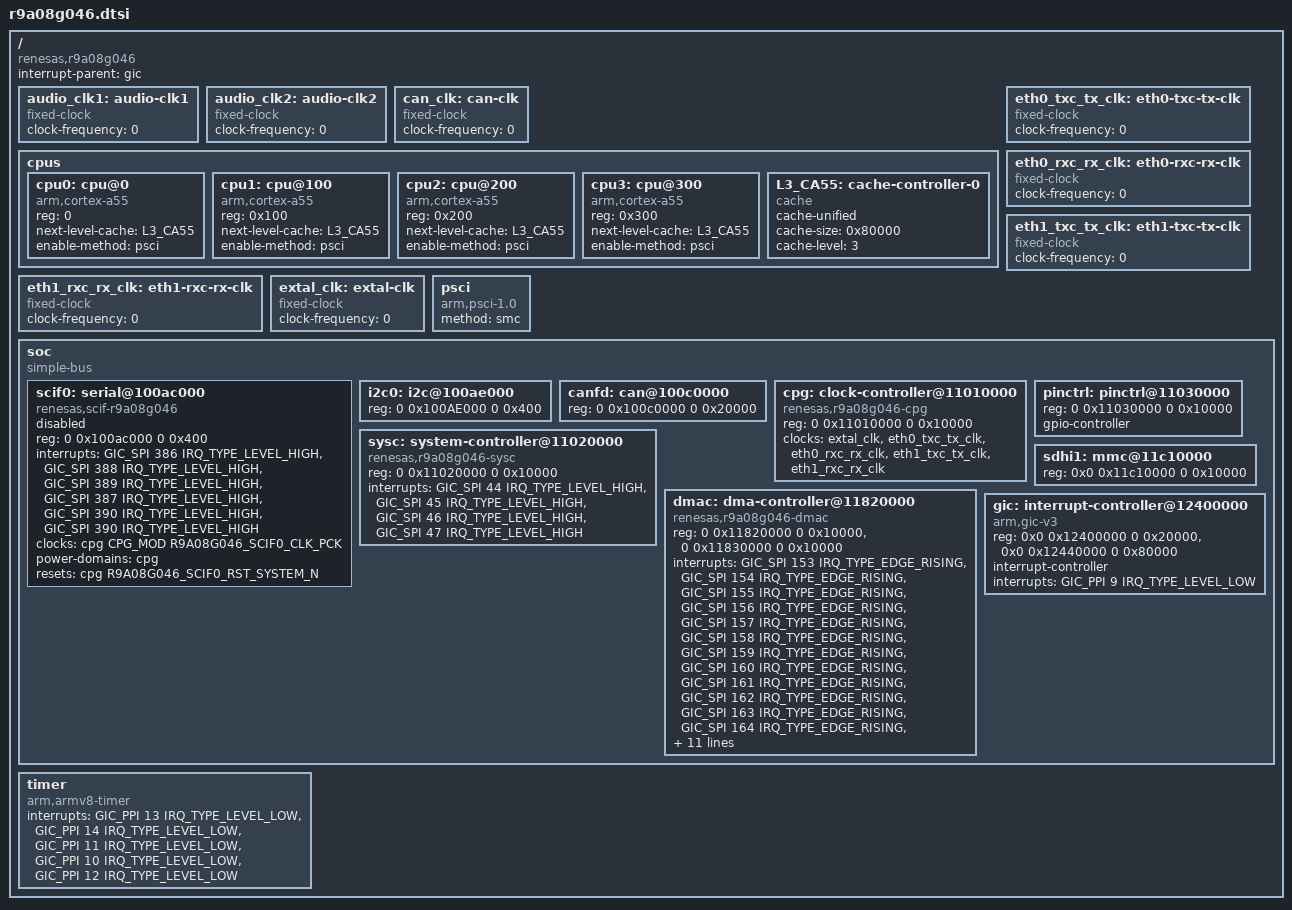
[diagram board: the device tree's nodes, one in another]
// SPDX-License-Identifier: (GPL-2.0-only OR BSD-2-Clause)
/*
 * Device Tree Source for the RZ/G3L SoC
 *
 * Copyright (C) 2026 Renesas Electronics Corp.
 */

#include <dt-bindings/clock/r9a08g046-cpg.h>
#include <dt-bindings/interrupt-controller/arm-gic.h>

/ {
	compatible = "renesas,r9a08g046";
	#address-cells = <2>;
	#size-cells = <2>;
	interrupt-parent = <&gic>;

	audio_clk1: audio-clk1 {
		compatible = "fixed-clock";
		#clock-cells = <0>;
		/* This value must be overridden by boards that provide it. */
		clock-frequency = <0>;
	};

	audio_clk2: audio-clk2 {
		compatible = "fixed-clock";
		#clock-cells = <0>;
		/* This value must be overridden by boards that provide it. */
		clock-frequency = <0>;
	};

	can_clk: can-clk {
		compatible = "fixed-clock";
		#clock-cells = <0>;
		/* This value must be overridden by boards that provide it. */
		clock-frequency = <0>;
	};

	cpus {
		#address-cells = <1>;
		#size-cells = <0>;

		cpu0: cpu@0 {
			compatible = "arm,cortex-a55";
			reg = <0>;
			device_type = "cpu";
			next-level-cache = <&L3_CA55>;
			enable-method = "psci";
		};

		cpu1: cpu@100 {
			compatible = "arm,cortex-a55";
			reg = <0x100>;
			device_type = "cpu";
			next-level-cache = <&L3_CA55>;
			enable-method = "psci";
		};

		cpu2: cpu@200 {
			compatible = "arm,cortex-a55";
			reg = <0x200>;
			device_type = "cpu";
			next-level-cache = <&L3_CA55>;
			enable-method = "psci";
		};

		cpu3: cpu@300 {
			compatible = "arm,cortex-a55";
			reg = <0x300>;
			device_type = "cpu";
			next-level-cache = <&L3_CA55>;
			enable-method = "psci";
		};

		L3_CA55: cache-controller-0 {
			compatible = "cache";
			cache-unified;
			cache-size = <0x80000>;
			cache-level = <3>;
		};
	};

	eth0_txc_tx_clk: eth0-txc-tx-clk {
		compatible = "fixed-clock";
		#clock-cells = <0>;
		/* This value must be overridden by the board */
		clock-frequency = <0>;
	};

	eth0_rxc_rx_clk: eth0-rxc-rx-clk {
		compatible = "fixed-clock";
		#clock-cells = <0>;
		/* This value must be overridden by the board */
		clock-frequency = <0>;
	};

	eth1_txc_tx_clk: eth1-txc-tx-clk {
		compatible = "fixed-clock";
		#clock-cells = <0>;
		/* This value must be overridden by the board */
		clock-frequency = <0>;
	};

	eth1_rxc_rx_clk: eth1-rxc-rx-clk {
		compatible = "fixed-clock";
		#clock-cells = <0>;
		/* This value must be overridden by the board */
		clock-frequency = <0>;
	};

	extal_clk: extal-clk {
		compatible = "fixed-clock";
		#clock-cells = <0>;
		/* This value must be overridden by the board. */
		clock-frequency = <0>;
	};

	psci {
		compatible = "arm,psci-1.0", "arm,psci-0.2";
		method = "smc";
	};

	soc: soc {
		compatible = "simple-bus";
		#address-cells = <2>;
		#size-cells = <2>;
		ranges;

		scif0: serial@100ac000 {
			compatible = "renesas,scif-r9a08g046", "renesas,scif-r9a07g044";
			reg = <0 0x100ac000 0 0x400>;
			interrupts = <GIC_SPI 386 IRQ_TYPE_LEVEL_HIGH>,
				     <GIC_SPI 388 IRQ_TYPE_LEVEL_HIGH>,
				     <GIC_SPI 389 IRQ_TYPE_LEVEL_HIGH>,
				     <GIC_SPI 387 IRQ_TYPE_LEVEL_HIGH>,
				     <GIC_SPI 390 IRQ_TYPE_LEVEL_HIGH>,
				     <GIC_SPI 390 IRQ_TYPE_LEVEL_HIGH>;
			interrupt-names = "eri", "rxi", "txi",
					  "bri", "dri", "tei";
			clocks = <&cpg CPG_MOD R9A08G046_SCIF0_CLK_PCK>;
			clock-names = "fck";
			power-domains = <&cpg>;
			resets = <&cpg R9A08G046_SCIF0_RST_SYSTEM_N>;
			status = "disabled";
		};

		i2c0: i2c@100ae000 {
			#address-cells = <1>;
			#size-cells = <0>;
			reg = <0 0x100AE000 0 0x400>;
			/* placeholder */
		};

		canfd: can@100c0000 {
			reg = <0 0x100c0000 0 0x20000>;
			/* placeholder */
		};

		cpg: clock-controller@11010000 {
			compatible = "renesas,r9a08g046-cpg";
			reg = <0 0x11010000 0 0x10000>;
			clocks = <&extal_clk>,
				 <&eth0_txc_tx_clk>, <&eth0_rxc_rx_clk>,
				 <&eth1_txc_tx_clk>, <&eth1_rxc_rx_clk>;
			clock-names = "extal",
				      "eth0_txc_tx_clk", "eth0_rxc_rx_clk",
				      "eth1_txc_tx_clk", "eth1_rxc_rx_clk";
			#clock-cells = <2>;
			#reset-cells = <1>;
			#power-domain-cells = <0>;
		};

		sysc: system-controller@11020000 {
			compatible = "renesas,r9a08g046-sysc";
			reg = <0 0x11020000 0 0x10000>;
			interrupts = <GIC_SPI 44 IRQ_TYPE_LEVEL_HIGH>,
				     <GIC_SPI 45 IRQ_TYPE_LEVEL_HIGH>,
				     <GIC_SPI 46 IRQ_TYPE_LEVEL_HIGH>,
				     <GIC_SPI 47 IRQ_TYPE_LEVEL_HIGH>;
			interrupt-names = "lpm_int", "ca55stbydone_int",
					  "cm33stbyr_int", "ca55_deny";
		};

		pinctrl: pinctrl@11030000 {
			reg = <0 0x11030000 0 0x10000>;
			gpio-controller;
			#gpio-cells = <2>;
		};

		dmac: dma-controller@11820000 {
			compatible = "renesas,r9a08g046-dmac", "renesas,rz-dmac";
			reg = <0 0x11820000 0 0x10000>,
			      <0 0x11830000 0 0x10000>;
			interrupts = <GIC_SPI 153 IRQ_TYPE_EDGE_RISING>,
				     <GIC_SPI 154 IRQ_TYPE_EDGE_RISING>,
				     <GIC_SPI 155 IRQ_TYPE_EDGE_RISING>,
				     <GIC_SPI 156 IRQ_TYPE_EDGE_RISING>,
				     <GIC_SPI 157 IRQ_TYPE_EDGE_RISING>,
				     <GIC_SPI 158 IRQ_TYPE_EDGE_RISING>,
				     <GIC_SPI 159 IRQ_TYPE_EDGE_RISING>,
				     <GIC_SPI 160 IRQ_TYPE_EDGE_RISING>,
				     <GIC_SPI 161 IRQ_TYPE_EDGE_RISING>,
				     <GIC_SPI 162 IRQ_TYPE_EDGE_RISING>,
				     <GIC_SPI 163 IRQ_TYPE_EDGE_RISING>,
				     <GIC_SPI 164 IRQ_TYPE_EDGE_RISING>,
				     <GIC_SPI 165 IRQ_TYPE_EDGE_RISING>,
				     <GIC_SPI 166 IRQ_TYPE_EDGE_RISING>,
				     <GIC_SPI 167 IRQ_TYPE_EDGE_RISING>,
				     <GIC_SPI 168 IRQ_TYPE_EDGE_RISING>,
				     <GIC_SPI 169 IRQ_TYPE_EDGE_RISING>;
			interrupt-names = "error",
					  "ch0", "ch1", "ch2", "ch3",
					  "ch4", "ch5", "ch6", "ch7",
					  "ch8", "ch9", "ch10", "ch11",
					  "ch12", "ch13", "ch14", "ch15";
			clocks = <&cpg CPG_MOD R9A08G046_DMAC_ACLK>,
				 <&cpg CPG_MOD R9A08G046_DMAC_PCLK>;
			clock-names = "main", "register";
			power-domains = <&cpg>;
			resets = <&cpg R9A08G046_DMAC_ARESETN>,
				 <&cpg R9A08G046_DMAC_RST_ASYNC>;
			reset-names = "arst", "rst_async";
			#dma-cells = <1>;
			dma-channels = <16>;
		};

		sdhi1: mmc@11c10000 {
			reg = <0x0 0x11c10000 0 0x10000>;
			/* placeholder */
		};

		gic: interrupt-controller@12400000 {
			compatible = "arm,gic-v3";
			reg = <0x0 0x12400000 0 0x20000>,
			      <0x0 0x12440000 0 0x80000>;
			#interrupt-cells = <3>;
			#address-cells = <0>;
			interrupt-controller;
			interrupts = <GIC_PPI 9 IRQ_TYPE_LEVEL_LOW>;
		};
	};

	timer {
		compatible = "arm,armv8-timer";
		interrupts = <GIC_PPI 13 IRQ_TYPE_LEVEL_LOW>,
			     <GIC_PPI 14 IRQ_TYPE_LEVEL_LOW>,
			     <GIC_PPI 11 IRQ_TYPE_LEVEL_LOW>,
			     <GIC_PPI 10 IRQ_TYPE_LEVEL_LOW>,
			     <GIC_PPI 12 IRQ_TYPE_LEVEL_LOW>;
		interrupt-names = "sec-phys", "phys", "virt", "hyp-phys", "hyp-virt";
	};
};
